/*---------GLOBAL DEFINITIONS-----------*/
LIN_description_file;
LIN_protocol_version = "2.1";
LIN_language_version = "2.1";
LIN_speed = 19.2 kbps;
/* ----------NODE DEFINITIONS---------- */
Nodes {
   Master:
      BCM, /* Master node name */
      5.0 ms, /* Time base */
      0.1 ms; /* Jitter */
   Slaves:
      RLS;
}
/* ----------SIGNAL DEFINITIONS---------- */
Signals {
   /* Signal_name : Size, Init, Publisher, Subscriber(s) */
   Ignition : 1, 0x1, BCM, RLS;
   SCS_Automatic : 1, 0x1, BCM, RLS;
   VehicleSpeed : 8, 0x0, BCM, RLS;
   Status_SMA : 3, 0x0, BCM, RLS;
   SCS_IntervalLeve : 4, 0x0, BCM, RLS;
   SCS_FrontWash : 1, 0x0, BCM, RLS;
   LS_Sensitivity : 3, 0x0, BCM, RLS;
   RS_Sensitivity : 3, 0x0, BCM, RLS;
   RS_Deactivation : 1, 0x0, BCM, RLS;
   Wiper_running : 1, 0x0, BCM, RLS;
   BladesTurningPoint : 1, 0x0, BCM, RLS;
   ParkPosition : 1, 0x0, BCM, RLS;
   SensorMsgCounter : 4, 0x0, RLS, BCM;
   LightSignalReady : 1, 0x0, RLS, BCM;
   Light_On : 1, 0x0, RLS, BCM;
   Light_On_Invers : 1, 0x0, RLS, BCM;
   Twilight_On : 1, 0x0, RLS, BCM;
   Twilight_On_Invers : 1, 0x0, RLS, BCM;
   LS_Error : 1, 0x0, RLS, BCM;
   LIN_Error : 1, 0x0, RLS, BCM;
   Brightness_FW : 10, 0x0, RLS, BCM;
   Brightness_IR_L : 8, 0x0, RLS, BCM;
   Brightness_IR_R : 8, 0x0, RLS, BCM;
   RS_Error : 1, 0x0, RLS, BCM;
   RainIntensity : 4, 0x0, RLS, BCM;
   WiperSpeed : 3, 0x0, RLS, BCM;
   Splash : 1, 0x0, RLS, BCM;
}
/* ----------DIAGNOSTIC SIGNAL DEFINITIONS---------- */
Diagnostic_signals {
   /* MasterReq Reserved Signals */
   MasterReqB0 : 8, 0;
   MasterReqB1 : 8, 0;
   MasterReqB2 : 8, 0;
   MasterReqB3 : 8, 0;
   MasterReqB4 : 8, 0;
   MasterReqB5 : 8, 0;
   MasterReqB6 : 8, 0;
   MasterReqB7 : 8, 0;
   /* SlaveResp Reserved Signals */
   SlaveRespB0 : 8, 0;
   SlaveRespB1 : 8, 0;
   SlaveRespB2 : 8, 0;
   SlaveRespB3 : 8, 0;
   SlaveRespB4 : 8, 0;
   SlaveRespB5 : 8, 0;
   SlaveRespB6 : 8, 0;
   SlaveRespB7 : 8, 0;
}
/* ----------UNCONDITIONAL FRAME DEFINITIONS---------- */
Frames {
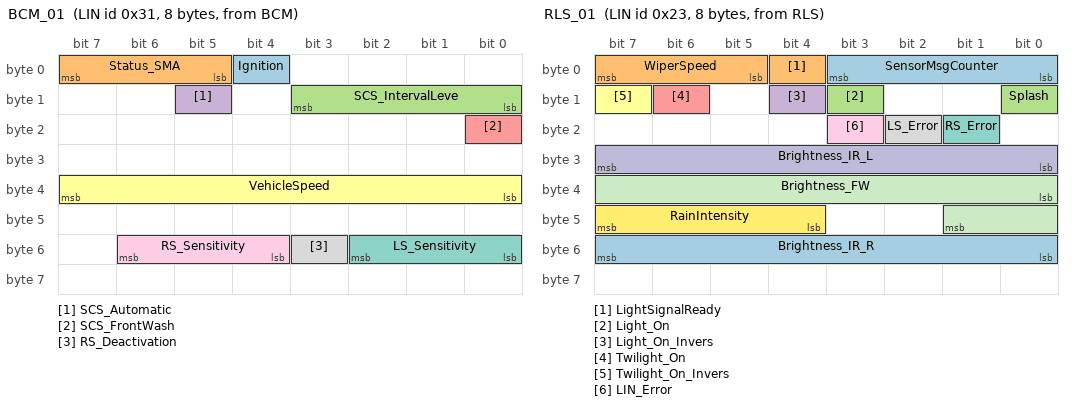
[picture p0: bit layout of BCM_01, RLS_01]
   BCM_01 : 0x31, BCM , 8 {
      Ignition , 4;
      Status_SMA , 5;
      SCS_IntervalLeve , 8;
      SCS_Automatic , 13;
      SCS_FrontWash , 16;
      VehicleSpeed , 32;
      LS_Sensitivity , 48;
      RS_Deactivation , 51;
      RS_Sensitivity , 52;
   }
   RLS_01 : 0x23, RLS , 8 {
      SensorMsgCounter , 0;
      LightSignalReady , 4;
      Light_On , 11;
      Light_On_Invers , 12;
      Twilight_On , 14;
      Twilight_On_Invers , 15;
      RS_Error , 17;
      LS_Error , 18;
      LIN_Error , 19;
      Brightness_IR_L , 24;
      Brightness_FW , 32;
      RainIntensity , 44;
      Brightness_IR_R , 48;
      WiperSpeed , 5;
      Splash , 8;
   }
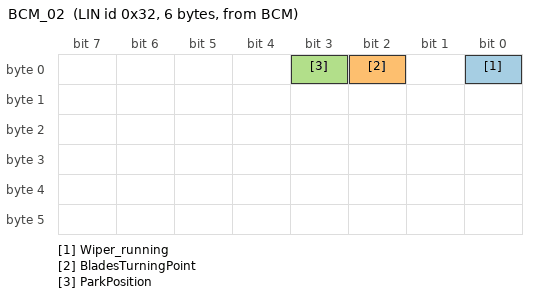
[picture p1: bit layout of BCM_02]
   BCM_02 : 0x32, BCM , 6 {
      Wiper_running , 0;
      BladesTurningPoint , 2;
      ParkPosition , 3;
   }
}
/* ----------DIAGNOSTIC FRAME DEFINITIONS---------- */
Diagnostic_frames {
   MasterReq : 0x3c {
      MasterReqB0 , 0;
      MasterReqB1 , 8;
      MasterReqB2 , 16;
      MasterReqB3 , 24;
      MasterReqB4 , 32;
      MasterReqB5 , 40;
      MasterReqB6 , 48;
      MasterReqB7 , 56;
   }
   SlaveResp : 0x3d {
      SlaveRespB0 , 0;
      SlaveRespB1 , 8;
      SlaveRespB2 , 16;
      SlaveRespB3 , 24;
      SlaveRespB4 , 32;
      SlaveRespB5 , 40;
      SlaveRespB6 , 48;
      SlaveRespB7 , 56;
   }
}
/* ----------NODE ATTRIBUTE DEFINITIONS---------- */
Node_attributes {
   RLS {
      LIN_protocol = "2.1"; /* Node protocol version */
      configured_NAD = 0x16; /* configured NAD of node (1-125) */
      initial_NAD = 0x16; /* initial NAD of node (1-125) */
      product_id = 0x23, 0x23, 0xff; /* Product id */
      response_error = LIN_Error; /* Response error signal */
      P2_min = 50 ms; /* P2_min */
      ST_min = 20 ms; /* ST_min */
      N_As_timeout = 1000 ms; /* N_As timeout value */
      N_Cr_timeout = 1000 ms; /* N_Cr timeout value */
      configurable_frames {
         RLS_01;
         BCM_01;
         BCM_02;
      }
   }
}
/* ----------SCHEDULE TABLE DEFINITIONS---------- */
Schedule_tables {
   NormalTable {
      BCM_01 delay 10.0 ms;
      RLS_01 delay 10.0 ms;
      BCM_02 delay 10.0 ms;
   }
   Diagnose {
      MasterReq delay 10.0 ms;
   }
}
/* ----------SIGNAL ENCODDING DEFINITIONS---------- */
Signal_encoding_types {
   Brightness_IR_L_Encoding {
      physical_value,0,0,4.0,0.0,"w/m2";
   }
}
/* ----------SIGNAL REPRESENTATION DEFINITIONS---------- */
Signal_representation {
   Brightness_IR_L_Encoding:Brightness_IR_L, Brightness_IR_R;
}
